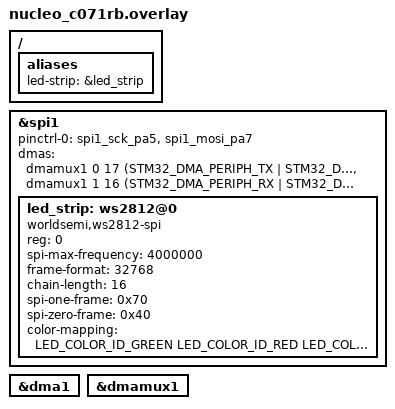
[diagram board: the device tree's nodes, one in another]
/*
 * Copyright (c) 2021, STMicroelectronics
 * Copyright (c) 2026, Framework Computer Inc
 *
 * SPDX-License-Identifier: Apache-2.0
 */
#include <zephyr/dt-bindings/dma/stm32_dma.h>
#include <zephyr/dt-bindings/led/led.h>

&spi1 {
	/* Use pin PA7, labeled as D11/MOSI on the C071RB */
	/* SCK is unused, but needs to be enabled for the SPI controller to function */
	pinctrl-0 = <&spi1_sck_pa5 &spi1_mosi_pa7>;
	pinctrl-names = "default";
	status = "okay";
	dmas = <&dmamux1 0 17 (STM32_DMA_PERIPH_TX | STM32_DMA_PRIORITY_LOW)>,
	       <&dmamux1 1 16 (STM32_DMA_PERIPH_RX | STM32_DMA_PRIORITY_LOW)>;
	dma-names = "tx", "rx";

	led_strip: ws2812@0 {
		compatible = "worldsemi,ws2812-spi";

		/* SPI */
		reg = <0>; /* ignored, but necessary for SPI bindings */
		spi-max-frequency = <4000000>;
		frame-format = <32768>; /* SPI_FRAME_FORMAT_TI */

		/* WS2812 */
		chain-length = <16>; /* arbitrary; change at will */
		spi-one-frame = <0x70>;
		spi-zero-frame = <0x40>;
		color-mapping = <LED_COLOR_ID_GREEN
				 LED_COLOR_ID_RED
				 LED_COLOR_ID_BLUE>;
	};
};

/ {
	aliases {
		led-strip = &led_strip;
	};
};

&dma1 {
	status = "okay";
};

&dmamux1 {
	status = "okay";
};
